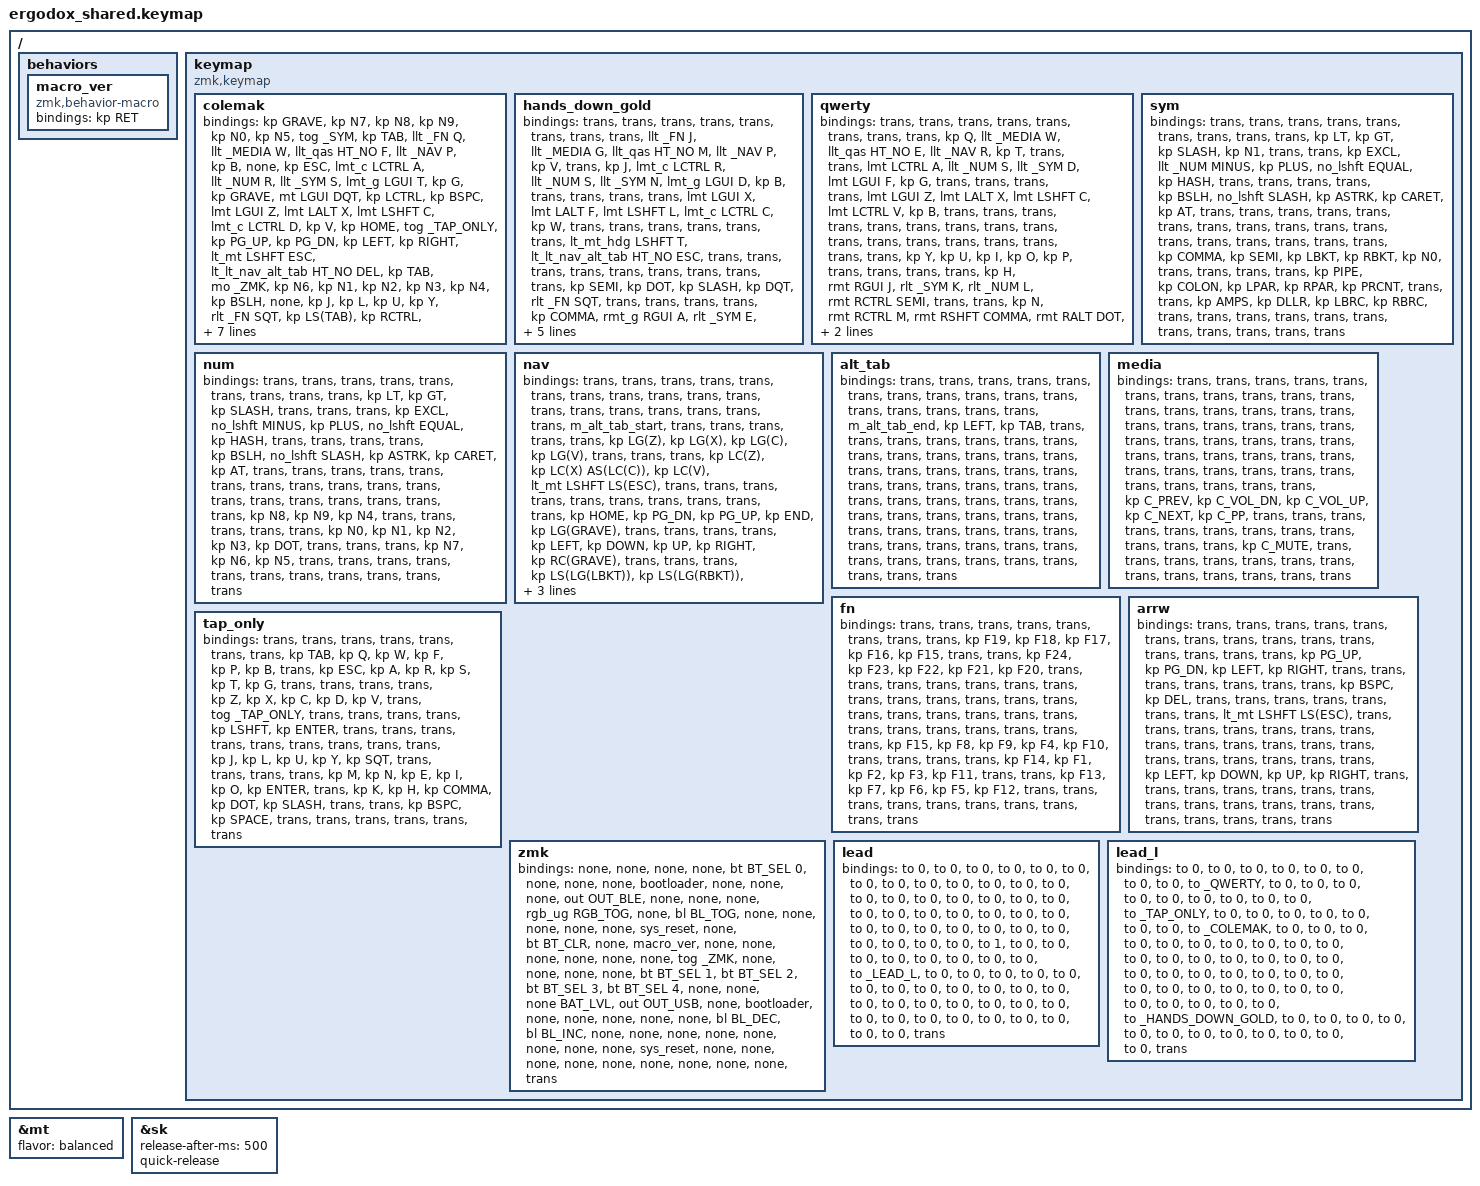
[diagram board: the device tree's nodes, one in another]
#include <behaviors.dtsi>
#include <dt-bindings/zmk/keys.h>
#include <dt-bindings/zmk/bt.h>
#include <dt-bindings/zmk/rgb.h>
#include <dt-bindings/zmk/backlight.h>
#include <dt-bindings/zmk/outputs.h>

#include "keyboards_conditional.dtsi"
#include "layers.dtsi"
#include "behaviors.dtsi"
#include "combos.dtsi"
#include "hold_tap.dtsi"
#include "macros.dtsi"

// Built-in Behavior tweaks
&mt {
  flavor = "balanced";
};
&sk {
  release-after-ms = <500>;
  // deactivate sticky key on next key press, instead of next key release
  quick-release;
};

/ {
  behaviors {
    #include "version.dtsi"
    #ifndef VERSION_MACRO
    macro_ver: macro_ver {
      compatible = "zmk,behavior-macro";
      #binding-cells = <0>;
      bindings = <&kp RET>;
    };
    #endif
  };

  keymap {
    compatible = "zmk,keymap";

    // TODO: add curly single and double quote symbols somewhere in the keymap
    // TODO: See if a layer without any mod-tap keys will work at the MacOS
    // filevault login screen
    colemak {
      bindings = <
        /* LH */
        &kp GRAVE       &kp N7          &kp N8         &kp N9            &kp N0          &kp N5  &tog _SYM
        &kp TAB         &llt _FN Q      &llt _MEDIA W  &llt_qas HT_NO F  &llt _NAV P     &kp B   &none
        &kp ESC         &lmt_c LCTRL A  &llt _NUM R    &llt _SYM S       &lmt_g LGUI T   &kp G   &kp GRAVE         &mt LGUI DQT                  &kp LCTRL
        &kp BSPC        &lmt LGUI Z     &lmt LALT X    &lmt LSHFT C      &lmt_c LCTRL D  &kp V                                                   &kp HOME
        &tog _TAP_ONLY  &kp PG_UP       &kp PG_DN      &kp LEFT          &kp RIGHT               &lt_mt LSHFT ESC  &lt_lt_nav_alt_tab HT_NO DEL  &kp TAB

        /* RH */
                                 &mo _ZMK            &kp N6  &kp N1         &kp N2            &kp N3         &kp N4           &kp BSLH
                                 &none               &kp J   &kp L          &kp U             &kp Y          &rlt _FN SQT     &kp LS(TAB)
        &kp RCTRL  &mt LGUI SQT  &kp DQT             &kp M   &rmt_g RGUI N  &rlt _SYM E       &rlt _NUM I    &rmt RCTRL O     &kp ENTER
        &kp PG_UP                                    &kp K   &rmt RCTRL H   &rmt RSHFT COMMA  &rmt RALT DOT  &rmt RGUI SLASH  &kp DEL
        &kp TAB    &kp BSPC      &rt_lt _ARRW SPACE          &kp DOWN       &kp UP            &kp LBKT       &kp RBKT         &mo _SYM

        /* SliceMK Ergodox */
        &sys_off
      >;
    };

    hands_down_gold {
      bindings = <
        /* LH */
        &trans  &trans          &trans         &trans            &trans          &trans  &trans
        &trans  &llt _FN J      &llt _MEDIA G  &llt_qas HT_NO M  &llt _NAV P     &kp V   &trans
        &kp J   &lmt_c LCTRL R  &llt _NUM S    &llt _SYM N       &lmt_g LGUI D   &kp B   &trans              &trans                        &trans
        &trans  &lmt LGUI X     &lmt LALT F    &lmt LSHFT L      &lmt_c LCTRL C  &kp W                                                     &trans
        &trans  &trans          &trans         &trans            &trans                  &lt_mt_hdg LSHFT T  &lt_lt_nav_alt_tab HT_NO ESC  &trans

        /* RH */
                        &trans  &trans     &trans         &trans        &trans       &trans        &trans
                        &trans  &kp SEMI   &kp DOT        &kp SLASH     &kp DQT      &rlt _FN SQT  &trans
        &trans  &trans  &trans  &kp COMMA  &rmt_g RGUI A  &rlt _SYM E   &rlt _NUM I  &rmt RCTRL H  &trans
        &trans                  &kp MINUS  &rmt RCTRL U   &rmt RSHFT O  &rmt RALT Y  &rmt RGUI K   &trans
        &trans  &trans  &trans             &trans         &trans        &trans       &trans        &trans

        /* SliceMK Ergodox */
        &sys_off
      >;
    };

    qwerty {
      bindings = <
        /* LH */
        &trans  &trans        &trans         &trans            &trans        &trans  &trans
        &trans  &kp Q         &llt _MEDIA W  &llt_qas HT_NO E  &llt _NAV R   &kp T   &trans
        &trans  &lmt LCTRL A  &llt _NUM S    &llt _SYM D       &lmt LGUI F   &kp G   &trans  &trans  &trans
        &trans  &lmt LGUI Z   &lmt LALT X    &lmt LSHFT C      &lmt LCTRL V  &kp B                   &trans
        &trans  &trans        &trans         &trans            &trans                &trans  &trans  &trans

        /* RH */
                        &trans  &trans  &trans        &trans            &trans         &trans           &trans
                        &trans  &kp Y   &kp U         &kp I             &kp  O         &kp P            &trans
        &trans  &trans  &trans  &kp H   &rmt RGUI J   &rlt _SYM K       &rlt _NUM L    &rmt RCTRL SEMI  &trans
        &trans                  &kp N   &rmt RCTRL M  &rmt RSHFT COMMA  &rmt RALT DOT  &rmt RGUI SLASH  &trans
        &trans  &trans  &trans          &trans        &trans            &trans         &trans           &trans

        /* SliceMK Ergodox */
        &trans
      >;
    };

    sym {
      bindings = <
        /* LH */
        &trans  &trans    &trans           &trans     &trans           &trans    &trans
        &trans  &trans    &kp LT           &kp GT     &kp SLASH        &kp N1    &trans
        &trans  &kp EXCL  &llt _NUM MINUS  &kp PLUS   &no_lshft EQUAL  &kp HASH  &trans  &trans  &trans
        &trans  &kp BSLH  &no_lshft SLASH  &kp ASTRK  &kp CARET        &kp AT                    &trans
        &trans  &trans    &trans           &trans     &trans                     &trans  &trans  &trans

        /* RH */
                        &trans  &trans    &trans     &trans    &trans    &trans     &trans
                        &trans  &kp COMMA &kp SEMI   &kp LBKT  &kp RBKT  &kp N0     &trans
        &trans  &trans  &trans  &kp PIPE  &kp COLON  &kp LPAR  &kp RPAR  &kp PRCNT  &trans
        &trans                  &kp AMPS  &kp DLLR   &kp LBRC  &kp RBRC  &trans     &trans
        &trans  &trans  &trans            &trans     &trans    &trans    &trans     &trans

        /* SliceMK Ergodox */
        &trans
      >;
    };

    num {
      bindings = <
        /* LH */
        &trans  &trans    &trans           &trans     &trans           &trans    &trans
        &trans  &trans    &kp LT           &kp GT     &kp SLASH        &trans    &trans
        &trans  &kp EXCL  &no_lshft MINUS  &kp PLUS   &no_lshft EQUAL  &kp HASH  &trans  &trans  &trans
        &trans  &kp BSLH  &no_lshft SLASH  &kp ASTRK  &kp CARET        &kp AT                    &trans
        &trans  &trans    &trans           &trans     &trans                     &trans  &trans  &trans

        /* RH */
                        &trans  &trans  &trans  &trans  &trans  &trans   &trans
                        &trans  &trans  &kp N8  &kp N9  &kp N4  &trans   &trans
        &trans  &trans  &trans  &kp N0  &kp N1  &kp N2  &kp N3  &kp DOT  &trans
        &trans                  &trans  &kp N7  &kp N6  &kp N5  &trans   &trans
        &trans  &trans  &trans          &trans  &trans  &trans  &trans   &trans

        /* SliceMK Ergodox */
        &trans
      >;
    };

    nav {
      bindings = <
        /* LH */
        &trans  &trans     &trans     &trans     &trans            &trans  &trans
        &trans  &trans     &trans     &trans     &trans            &trans  &trans
        &trans  &trans     &trans     &trans     &m_alt_tab_start  &trans  &trans                &trans  &trans
        &trans  &kp LG(Z)  &kp LG(X)  &kp LG(C)  &kp LG(V)         &trans                                &trans
        &trans  &kp LC(Z)  &kp LC(X)  AS(LC(C))  &kp LC(V)                 &lt_mt LSHFT LS(ESC)  &trans  &trans

        /* RH */
                        &trans  &trans    &trans            &trans            &trans          &trans            &trans
                        &trans  &kp HOME  &kp PG_DN         &kp PG_UP         &kp END         &kp LG(GRAVE)     &trans
        &trans  &trans  &trans  &kp LEFT  &kp DOWN          &kp UP            &kp RIGHT       &kp RC(GRAVE)     &trans
        &trans                  &trans    &kp LS(LG(LBKT))  &kp LS(LG(RBKT))  &kp LC(LEFT)    &kp LC(RIGHT)     &trans
        &trans  &trans  &trans            &kp LC(PG_UP)     &kp LC(PG_DN)     &kp LC(LA(UP))  &kp LC(LA(DOWN))  &trans

        /* SliceMK Ergodox */
        &trans
      >;
    };

    alt_tab {
      bindings = <
        /* LH */
        &trans  &trans  &trans          &trans    &trans   &trans  &trans
        &trans  &trans  &trans          &trans    &trans   &trans  &trans
        &trans  &trans  &m_alt_tab_end  &kp LEFT  &kp TAB  &trans  &trans  &trans  &trans
        &trans  &trans  &trans          &trans    &trans   &trans                  &trans
        &trans  &trans  &trans          &trans    &trans           &trans  &trans  &trans

        /* RH */
                        &trans  &trans  &trans  &trans  &trans  &trans  &trans
                        &trans  &trans  &trans  &trans  &trans  &trans  &trans
        &trans  &trans  &trans  &trans  &trans  &trans  &trans  &trans  &trans
        &trans                  &trans  &trans  &trans  &trans  &trans  &trans
        &trans  &trans  &trans          &trans  &trans  &trans  &trans  &trans

        /* SliceMK Ergodox */
        &trans
      >;
    };

    media {
      bindings = <
        /* LH */
        &trans  &trans  &trans  &trans  &trans  &trans  &trans
        &trans  &trans  &trans  &trans  &trans  &trans  &trans
        &trans  &trans  &trans  &trans  &trans  &trans  &trans  &trans  &trans
        &trans  &trans  &trans  &trans  &trans  &trans                  &trans
        &trans  &trans  &trans  &trans  &trans          &trans  &trans  &trans

        /* RH */
                        &trans  &trans      &trans        &trans        &trans      &trans    &trans
                        &trans  &kp C_PREV  &kp C_VOL_DN  &kp C_VOL_UP  &kp C_NEXT  &kp C_PP  &trans
        &trans  &trans  &trans  &trans      &trans        &trans        &trans      &trans    &trans
        &trans                  &trans      &kp C_MUTE    &trans        &trans      &trans    &trans
        &trans  &trans  &trans              &trans        &trans        &trans      &trans    &trans

        /* SliceMK Ergodox */
        &trans
      >;
    };

    // TODO: Rearrange these more logically, like with a grid on the left hand also
    fn {
      bindings = <
        /* LH */
        &trans  &trans   &trans   &trans   &trans   &trans   &trans
        &trans  &kp F19  &kp F18  &kp F17  &kp F16  &kp F15  &trans
        &trans  &kp F24  &kp F23  &kp F22  &kp F21  &kp F20  &trans  &trans  &trans
        &trans  &trans   &trans   &trans   &trans   &trans                   &trans
        &trans  &trans   &trans   &trans   &trans            &trans  &trans  &trans

        /* RH */
                        &trans  &trans   &trans  &trans  &trans  &trans   &trans
                        &trans  &kp F15  &kp F8  &kp F9  &kp F4  &kp F10  &trans
        &trans  &trans  &trans  &kp F14  &kp F1  &kp F2  &kp F3  &kp F11  &trans
        &trans                  &kp F13  &kp F7  &kp F6  &kp F5  &kp F12  &trans
        &trans  &trans  &trans           &trans  &trans  &trans  &trans   &trans

        /* SliceMK Ergodox */
        &trans
      >;
    };

    arrw {
      bindings = <
        /* LH */
        &trans  &trans     &trans     &trans    &trans     &trans  &trans
        &trans  &trans     &trans     &trans    &trans     &trans  &trans
        &trans  &kp PG_UP  &kp PG_DN  &kp LEFT  &kp RIGHT  &trans  &trans                &trans  &trans
        &trans  &trans     &trans     &kp BSPC  &kp DEL    &trans                                &trans
        &trans  &trans     &trans     &trans    &trans             &lt_mt LSHFT LS(ESC)  &trans  &trans

        /* RH */
                        &trans  &trans    &trans    &trans  &trans     &trans  &trans
                        &trans  &trans    &trans    &trans  &trans     &trans  &trans
        &trans  &trans  &trans  &kp LEFT  &kp DOWN  &kp UP  &kp RIGHT  &trans  &trans
        &trans                  &trans    &trans    &trans  &trans     &trans  &trans
        &trans  &trans  &trans            &trans    &trans  &trans     &trans  &trans

        /* SliceMK Ergodox */
        &trans
      >;
    };

    tap_only {
      bindings = <
        /* LH */
        &trans          &trans  &trans  &trans  &trans  &trans  &trans
        &kp TAB         &kp Q   &kp W   &kp F   &kp P   &kp B   &trans
        &kp ESC         &kp A   &kp R   &kp S   &kp T   &kp G   &trans     &trans     &trans
        &trans          &kp Z   &kp X   &kp C   &kp D   &kp V                         &trans
        &tog _TAP_ONLY  &trans  &trans  &trans  &trans          &kp LSHFT  &kp ENTER  &trans

        /* RH */
                          &trans     &trans  &trans  &trans     &trans   &trans     &trans
                          &trans     &kp J   &kp L   &kp U      &kp Y    &kp SQT    &trans
        &trans  &trans    &trans     &kp M   &kp N   &kp E      &kp I    &kp O      &kp ENTER
        &trans                       &kp K   &kp H   &kp COMMA  &kp DOT  &kp SLASH  &trans
        &trans  &kp BSPC  &kp SPACE          &trans  &trans     &trans   &trans     &trans

        /* SliceMK Ergodox */
        &trans
      >;
    };

    zmk {
      bindings = <
        /* LH */
        &none  &none        &none            &none       &bt BT_SEL 0  &none         &none
        &none  &bootloader  &none            &none       &none         &out OUT_BLE  &none
        &none  &none        &rgb_ug RGB_TOG  &none       &bl BL_TOG    &none         &none      &none  &none
        &none  &sys_reset   &none            &bt BT_CLR  &none         &macro_ver                      &none
        &none  &none        &none            &none       &none                       &tog _ZMK  &none  &none

        /* RH */
                      &none   &none  &bt BT_SEL 1  &bt BT_SEL 2  &bt BT_SEL 3  &bt BT_SEL 4  &none
                      &none   &none  BAT_LVL       &out OUT_USB  &none         &bootloader   &none
        &none  &none  &none   &none  &bl BL_DEC    &bl BL_INC    &none         &none         &none
        &none                 &none  &none         &none         &none         &sys_reset    &none
        &none  &none  &none          &none         &none         &none         &none         &none

        /* SliceMK Ergodox */
        &trans
      >;
    };

    lead {
      bindings = <
        /* LH */
        &to 0  &to 0  &to 0  &to 0  &to 0  &to 0  &to 0
        &to 0  &to 0  &to 0  &to 0  &to 0  &to 0  &to 0
        &to 0  &to 0  &to 0  &to 0  &to 0  &to 0  &to 0  &to 0  &to 0
        &to 0  &to 0  &to 0  &to 0  &to 0  &to 0                &to 0
        &to 0  &to 0  &to 0  &to 0  &to 0         &to 0  &to 0  &to 0

        /* RH */
                      &to 1  &to 0  &to 0        &to 0  &to 0  &to 0  &to 0
                      &to 0  &to 0  &to _LEAD_L  &to 0  &to 0  &to 0  &to 0
        &to 0  &to 0  &to 0  &to 0  &to 0        &to 0  &to 0  &to 0  &to 0
        &to 0                &to 0  &to 0        &to 0  &to 0  &to 0  &to 0
        &to 0  &to 0  &to 0         &to 0        &to 0  &to 0  &to 0  &to 0

        /* SliceMK Ergodox */
        &trans
      >;
    };

    lead_l {
      bindings = <
        /* LH */
        &to 0  &to 0        &to 0  &to 0         &to 0          &to 0  &to 0
        &to 0  &to _QWERTY  &to 0  &to 0         &to 0          &to 0  &to 0
        &to 0  &to 0        &to 0  &to 0         &to _TAP_ONLY  &to 0  &to 0  &to 0  &to 0
        &to 0  &to 0        &to 0  &to _COLEMAK  &to 0          &to 0                &to 0
        &to 0  &to 0        &to 0  &to 0         &to 0                 &to 0  &to 0  &to 0

        /* RH */
                      &to 0  &to 0  &to 0                 &to 0  &to 0  &to 0  &to 0
                      &to 0  &to 0  &to 0                 &to 0  &to 0  &to 0  &to 0
        &to 0  &to 0  &to 0  &to 0  &to 0                 &to 0  &to 0  &to 0  &to 0
        &to 0                &to 0  &to _HANDS_DOWN_GOLD  &to 0  &to 0  &to 0  &to 0
        &to 0  &to 0  &to 0         &to 0                 &to 0  &to 0  &to 0  &to 0

        /* SliceMK Ergodox */
        &trans
      >;
    };

    // lead_template {
    //   bindings = <
    //     /* LH */
    //     &to 0  &to 0  &to 0  &to 0  &to 0  &to 0  &to 0
    //     &to 0  &to 0  &to 0  &to 0  &to 0  &to 0  &to 0
    //     &to 0  &to 0  &to 0  &to 0  &to 0  &to 0  &to 0  &to 0  &to 0
    //     &to 0  &to 0  &to 0  &to 0  &to 0  &to 0                &to 0
    //     &to 0  &to 0  &to 0  &to 0  &to 0         &to 0  &to 0  &to 0
    //
    //     /* RH */
    //                   &to 0  &to 0  &to 0  &to 0  &to 0  &to 0  &to 0
    //                   &to 0  &to 0  &to 0  &to 0  &to 0  &to 0  &to 0
    //     &to 0  &to 0  &to 0  &to 0  &to 0  &to 0  &to 0  &to 0  &to 0
    //     &to 0                &to 0  &to 0  &to 0  &to 0  &to 0  &to 0
    //     &to 0  &to 0  &to 0         &to 0  &to 0  &to 0  &to 0  &to 0
    //
    //  /* SliceMK Ergodox */
    //  &trans
    //   >;
    // };

    // template {
    //   bindings = <
    //     /* LH */
    //     &trans  &trans  &trans  &trans  &trans  &trans  &trans
    //     &trans  &trans  &trans  &trans  &trans  &trans  &trans
    //     &trans  &trans  &trans  &trans  &trans  &trans  &trans  &trans  &trans
    //     &trans  &trans  &trans  &trans  &trans  &trans                  &trans
    //     &trans  &trans  &trans  &trans  &trans          &trans  &trans  &trans
    //
    //     /* RH */
    //                     &trans  &trans  &trans  &trans  &trans  &trans  &trans
    //                     &trans  &trans  &trans  &trans  &trans  &trans  &trans
    //     &trans  &trans  &trans  &trans  &trans  &trans  &trans  &trans  &trans
    //     &trans                  &trans  &trans  &trans  &trans  &trans  &trans
    //     &trans  &trans  &trans          &trans  &trans  &trans  &trans  &trans
    //
    //  /* SliceMK Ergodox */
    //  &trans
    //   >;
    // };
  };
};
